VERSION ""

NS_ :

BS_:

BU_: XXX

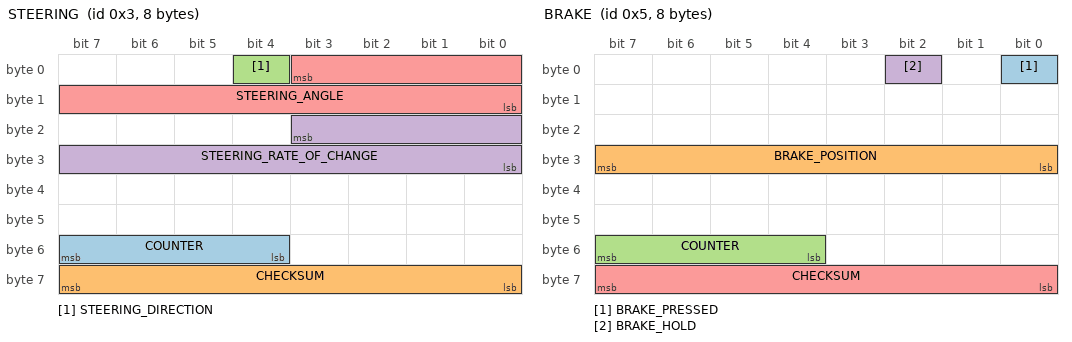
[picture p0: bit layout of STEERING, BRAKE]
BO_ 3 STEERING: 8 XXX
 SG_ COUNTER : 55|4@0+ (1,0) [0|15] "" XXX
 SG_ CHECKSUM : 63|8@0+ (1,0) [0|255] "" XXX
 SG_ STEERING_DIRECTION : 4|1@0+ (1,0) [0|1] "" XXX
 SG_ STEERING_RATE_OF_CHANGE : 19|12@0- (0.5,0) [0|255] "" XXX
 SG_ STEERING_ANGLE : 3|12@0- (0.5,0) [-500|500] "degrees" XXX

BO_ 5 BRAKE: 8 XXX
 SG_ BRAKE_PRESSED : 0|1@1+ (1,0) [0|1] "" XXX
 SG_ BRAKE_POSITION : 31|8@0+ (1,0) [0|65535] "" XXX
 SG_ COUNTER : 55|4@0+ (1,0) [0|15] "" XXX
 SG_ BRAKE_HOLD : 2|1@0+ (1,0) [0|1] "" XXX
 SG_ CHECKSUM : 63|8@0+ (1,0) [0|255] "" XXX

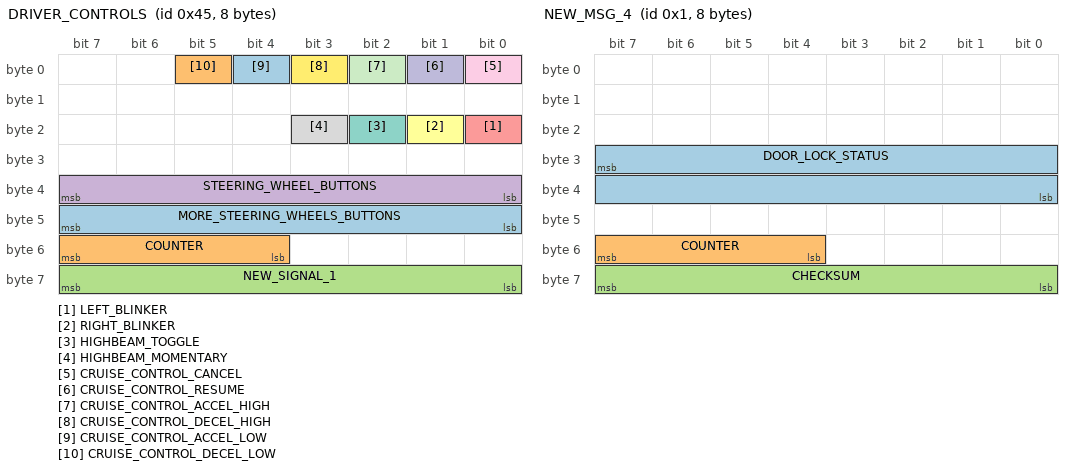
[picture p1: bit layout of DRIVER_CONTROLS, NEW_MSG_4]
BO_ 69 DRIVER_CONTROLS: 8 XXX
 SG_ MORE_STEERING_WHEELS_BUTTONS : 40|8@1+ (1,0) [0|255] "" XXX
 SG_ COUNTER : 55|4@0+ (1,0) [0|15] "" XXX
 SG_ NEW_SIGNAL_1 : 63|8@0+ (1,0) [0|255] "" XXX
 SG_ STEERING_WHEEL_BUTTONS : 32|8@1+ (1,0) [0|255] "4 directional, 2 volume control & 2 phone buttons" XXX
 SG_ LEFT_BLINKER : 16|1@0+ (1,0) [0|1] "" XXX
 SG_ RIGHT_BLINKER : 17|1@0+ (1,0) [0|1] "" XXX
 SG_ HIGHBEAM_TOGGLE : 18|1@0+ (1,0) [0|1] "" XXX
 SG_ HIGHBEAM_MOMENTARY : 19|1@0+ (1,0) [0|1] "" XXX
 SG_ CRUISE_CONTROL_CANCEL : 0|1@0+ (1,0) [0|1] "" XXX
 SG_ CRUISE_CONTROL_RESUME : 1|1@0+ (1,0) [0|1] "" XXX
 SG_ CRUISE_CONTROL_ACCEL_HIGH : 2|1@0+ (1,0) [0|1] "" XXX
 SG_ CRUISE_CONTROL_DECEL_HIGH : 3|1@0+ (1,0) [0|1] "" XXX
 SG_ CRUISE_CONTROL_ACCEL_LOW : 4|1@0+ (1,0) [0|1] "" XXX
 SG_ CRUISE_CONTROL_DECEL_LOW : 5|1@0+ (1,0) [0|1] "" XXX

BO_ 1 NEW_MSG_4: 8 XXX
 SG_ DOOR_LOCK_STATUS : 31|16@0+ (1,0) [0|65535] "" XXX
 SG_ COUNTER : 55|4@0+ (1,0) [0|15] "" XXX
 SG_ CHECKSUM : 63|8@0+ (1,0) [0|255] "" XXX

BO_ 581 NEW_MSG_5: 8 XXX
 SG_ COUNTER : 55|4@0+ (1,0) [0|15] "" XXX

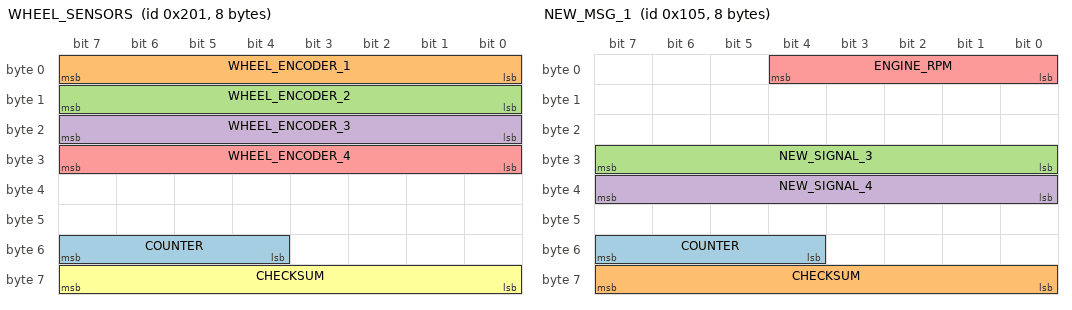
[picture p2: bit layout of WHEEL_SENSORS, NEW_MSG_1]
BO_ 513 WHEEL_SENSORS: 8 XXX
 SG_ COUNTER : 55|4@0+ (1,0) [0|15] "" XXX
 SG_ WHEEL_ENCODER_1 : 7|8@0+ (1,0) [0|255] "" XXX
 SG_ WHEEL_ENCODER_2 : 15|8@0+ (1,0) [0|255] "" XXX
 SG_ WHEEL_ENCODER_3 : 23|8@0+ (1,0) [0|255] "" XXX
 SG_ WHEEL_ENCODER_4 : 31|8@0+ (1,0) [0|255] "" XXX
 SG_ CHECKSUM : 56|8@1+ (1,0) [0|255] "" XXX

BO_ 261 NEW_MSG_1: 8 XXX
 SG_ COUNTER : 55|4@0+ (1,0) [0|15] "" XXX
 SG_ CHECKSUM : 63|8@0+ (1,0) [0|255] "" XXX
 SG_ NEW_SIGNAL_3 : 31|8@0+ (1,0) [0|255] "" XXX
 SG_ NEW_SIGNAL_4 : 39|8@0+ (1,0) [0|255] "" XXX
 SG_ ENGINE_RPM : 4|5@0+ (1,0) [0|255] "" XXX

BO_ 925 NEW_MSG_2: 8 XXX
 SG_ COUNTER : 62|4@0+ (1,0) [0|15] "" XXX

BO_ 643 NEW_MSG_3: 8 XXX
 SG_ DRIVER_DOOR : 1|2@0+ (1,0) [0|1] "" XXX
 SG_ PASSENGER_DOOR : 2|2@1+ (1,0) [0|3] "" XXX
 SG_ BACK_LEFT_DOOR : 5|2@0+ (1,0) [0|3] "" XXX
 SG_ BACK_RIGHT_DOOR : 7|3@0+ (1,0) [0|3] "" XXX
 SG_ BRAKE_PRESSED : 27|1@0+ (1,0) [0|1] "" XXX

BO_ 885 NEW_MSG_6: 8 XXX
 SG_ DRIVER_SEATBELT : 16|1@0+ (1,0) [0|1] "" XXX
 SG_ PASSENGER_SEATBELT : 18|1@0+ (1,0) [0|1] "" XXX

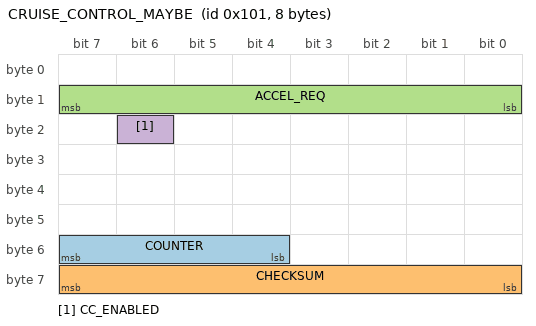
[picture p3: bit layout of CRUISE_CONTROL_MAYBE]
BO_ 257 CRUISE_CONTROL_MAYBE: 8 XXX
 SG_ COUNTER : 55|4@0+ (1,0) [0|15] "" XXX
 SG_ CHECKSUM : 63|8@0+ (1,0) [0|255] "" XXX
 SG_ ACCEL_REQ : 15|8@0+ (1,0) [0|127] "" XXX
 SG_ CC_ENABLED : 22|1@0+ (1,0) [0|1] "" XXX

CM_ SG_ 3 STEERING_DIRECTION "0 = left, 1 = right";
CM_ SG_ 69 MORE_STEERING_WHEELS_BUTTONS "back, ok, voice assistance, and mute buttons";
